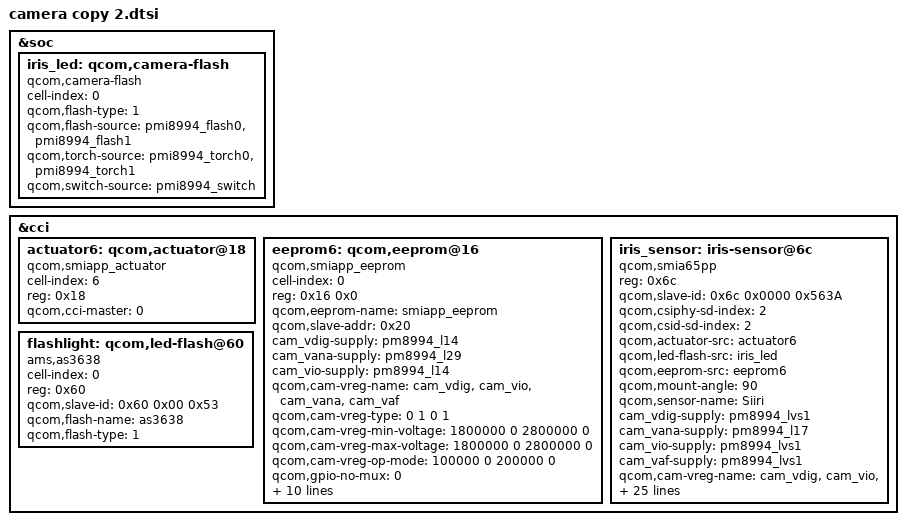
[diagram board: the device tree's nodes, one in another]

/*
 * Copyright (c) 2013, The Linux Foundation. All rights reserved.
 *
 * This program is free software; you can redistribute it and/or modify
 * it under the terms of the GNU General Public License version 2 and
 * only version 2 as published by the Free Software Foundation.
 *
 * This program is distributed in the hope that it will be useful,
 * but WITHOUT ANY WARRANTY; without even the implied warranty of
 * MERCHANTABILITY or FITNESS FOR A PARTICULAR PURPOSE.  See the
 * GNU General Public License for more details.
 */

&soc {
	//Iris LED
	iris_led: qcom,camera-flash {
		cell-index = <0>;
		compatible = "qcom,camera-flash";
		qcom,flash-type = <1>;
		qcom,flash-source = <&pmi8994_flash0 &pmi8994_flash1>;
		qcom,torch-source = <&pmi8994_torch0 &pmi8994_torch1>;
		qcom,switch-source = <&pmi8994_switch>;
	};
};


&cci {

	actuator6: qcom,actuator@18 {
		cell-index = <6>;
		reg = <0x18>;
		compatible = "qcom,smiapp_actuator";
		qcom,cci-master = <0>;
	};

	eeprom6: qcom,eeprom@16 {
		cell-index = <0>;
		reg = <0x16 0x0>;
		qcom,eeprom-name = "smiapp_eeprom";
		compatible = "qcom,smiapp_eeprom";
		qcom,slave-addr = <0x20>;
		
		cam_vdig-supply = <&pm8994_l14>;
		cam_vana-supply = <&pm8994_l29>;
		cam_vio-supply = <&pm8994_l14>;
		qcom,cam-vreg-name = "cam_vdig", "cam_vio", "cam_vana",
							 "cam_vaf";
		qcom,cam-vreg-type = <0 1 0 1>;
		qcom,cam-vreg-min-voltage = <1800000 0 2800000 0>;
		qcom,cam-vreg-max-voltage = <1800000 0 2800000 0>;
		qcom,cam-vreg-op-mode = <100000 0 200000 0>;
		qcom,gpio-no-mux = <0>;
		gpios = <&msm_gpio 106 0>;
		qcom,gpio-req-tbl-num = <0>;
		qcom,gpio-req-tbl-flags = <1 >;
		qcom,gpio-req-tbl-label = "CAMIF_MCLK";
	        qcom,cam-power-seq-type = "sensor_vreg",
			"sensor_vreg", "sensor_clk";
		qcom,cam-power-seq-val = "cam_vana",
			"cam_vdig", "sensor_cam_mclk";
		qcom,cam-power-seq-cfg-val = <1 1 9600000>;
		qcom,cam-power-seq-delay = <1 1 5>;

	};

// H1000/1 Siiri (IRIS CAM FPC) (Iris) (Toshiba) (T4KE1)
	iris_sensor: iris-sensor@6c {
		compatible = "qcom,smia65pp";
		reg = <0x6c>;
		qcom,slave-id = <0x6c 0x0000 0x563A>;
		qcom,csiphy-sd-index = <2>;
		qcom,csid-sd-index = <2>;
		qcom,actuator-src = <&actuator6>;
		qcom,led-flash-src = <&iris_led>;
		qcom,eeprom-src = <&eeprom6>;
		qcom,mount-angle = <90>;
		qcom,sensor-name = "Siiri";
		cam_vdig-supply = <&pm8994_lvs1>;
		cam_vana-supply = <&pm8994_l17>;
		cam_vio-supply = <&pm8994_lvs1>;
		cam_vaf-supply = <&pm8994_lvs1>;
		qcom,cam-vreg-name = "cam_vdig", "cam_vio", "cam_vana",
							 "cam_vaf";
		qcom,cam-vreg-type = <0 1 0 1>;
		qcom,cam-vreg-min-voltage = <1800000 0 2800000 0>;
		qcom,cam-vreg-max-voltage = <1800000 0 2800000 0>;
		qcom,cam-vreg-op-mode = <10000 0 100000 0>;
		qcom,gpio-no-mux = <0>;
		pinctrl-names = "cam_default", "cam_suspend";
		pinctrl-0 = <&cam_sensor_mclk1_active &cam_sensor_rear_active>;
		pinctrl-1 = <&cam_sensor_mclk1_suspend &cam_sensor_rear_suspend>;
		gpios = <&msm_gpio 14 0>,
				<&msm_gpio 102 0>,
				<&msm_gpio 106 0>;
		qcom,gpio-reset = <1>;
		qcom,gpio-standby = <2>;
		qcom,gpio-req-tbl-num = <0 1 2>;
		qcom,gpio-req-tbl-flags = <1 0 0>;
		qcom,gpio-req-tbl-label = "CAMIF_MCLK1",
					  "CAM_RESET1",
					  "CAM_STANDBY1";
		qcom,csi-lane-assign = <0x4320>;
		qcom,csi-lane-mask = <0x7>;
		qcom,sensor-position = <1>;
		qcom,sensor-mode = <1>;
		qcom,sensor-type = <0>;
		qcom,cci-master = <1>;
		status = "ok";
		clocks = <&clock_mmss clk_mclk1_clk_src>,
			<&clock_mmss clk_camss_mclk1_clk>;
		clock-names = "cam_src_clk", "cam_clk";
	};
	

   	flashlight: qcom,led-flash@60 {
	 	cell-index = <0>;
	 	reg = <0x60>;
	 	qcom,slave-id = <0x60 0x00 0x53>;
	 	compatible = "ams,as3638";
	 	qcom,flash-name = "as3638";
		qcom,flash-type = <1>;
    };

};
